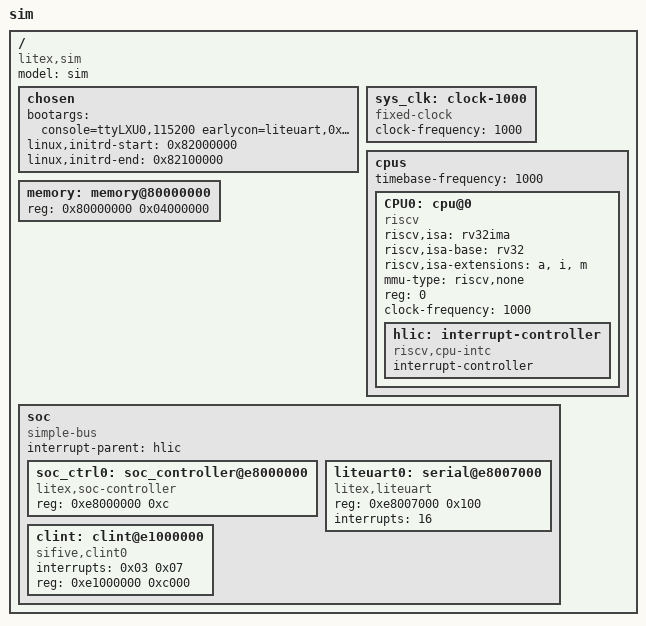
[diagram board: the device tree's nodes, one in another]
/dts-v1/;

/ {
    compatible = "litex,sim", "litex,soc";
    model = "sim";
    #address-cells = <1>;
    #size-cells    = <1>;

    chosen {
        bootargs = "console=ttyLXU0,115200 earlycon=liteuart,0xe8007000 lpj=90000 rootwait root=/dev/ram0 rw";
        linux,initrd-start = <0x82000000>;
        linux,initrd-end   = <0x82100000>;
    };

    sys_clk: clock-1000 {
        compatible = "fixed-clock";
        #clock-cells = <0>;
        clock-frequency  = <1000>;
    };

	cpus {
        #address-cells = <1>;
        #size-cells    = <0>;
        timebase-frequency = <1000>;

        CPU0: cpu@0 {
            device_type = "cpu";
            compatible = "riscv";
            riscv,isa = "rv32ima";
            riscv,isa-base = "rv32";
            riscv,isa-extensions = "a", "i", "m";
            mmu-type = "riscv,none";
            reg = <0>;
            clock-frequency = <1000>;
            status = "okay";

			hlic: interrupt-controller {
				compatible = "riscv,cpu-intc";
				#address-cells = <1>;
				#interrupt-cells = <1>;
				interrupt-controller;
			};
		};
	};

    memory: memory@80000000 {
        device_type = "memory";
        reg = <0x80000000 0x04000000>;
    };

    soc {
        #address-cells = <1>;
        #size-cells    = <1>;
        compatible = "simple-bus";
        interrupt-parent = <&hlic>;
        ranges;

        soc_ctrl0: soc_controller@e8000000 {
            compatible = "litex,soc-controller";
            reg = <0xe8000000 0xc>;
            status = "okay";
        };

        liteuart0: serial@e8007000 {
            compatible = "litex,liteuart";
            reg = <0xe8007000 0x100>;
            interrupts = <16>;
            status = "okay";
        };

        clint: clint@e1000000 {
			interrupts = <0x03 0x07>;
			reg = <0xe1000000 0xc000>;
			compatible = "sifive,clint0";
		};
    };

};
